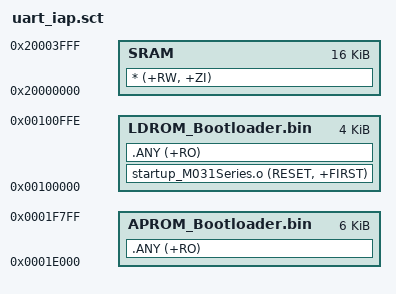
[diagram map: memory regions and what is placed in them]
LOAD_ROM_1  0x100000 0xFFF
{
	LDROM_Bootloader.bin  0x100000 0xFFF
	{
		startup_M031Series.o (RESET, +FIRST)
        .ANY (+RO)
	}
	
	SRAM  0x20000000 0x4000
	{
		* (+RW, +ZI)
	}
}

LOAD_ROM_2  0x1E000 0x1800
{
	APROM_Bootloader.bin  0x1E000 0x1800
	{
        .ANY (+RO)
	}
}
